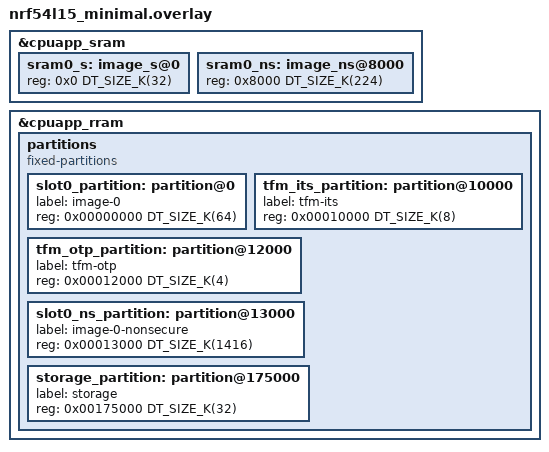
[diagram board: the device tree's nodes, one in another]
/*
 * Copyright (c) 2026 Nordic Semiconductor ASA
 *
 * SPDX-License-Identifier: LicenseRef-Nordic-5-Clause
 */

/*
 * Minimal TF-M partition layout for nRF54L15
 *
 * nRF54L15 has 1524 kB of RRAM and 256 kB of SRAM.
 * TrustZone flash region alignment: 4 kB (MPC-based)
 * TrustZone RAM region alignment:   4 kB
 * RRAM erase-block-size:            4 kB
 *
 * This layout uses the TF-M minimal profile with:
 * - No MCUboot (direct boot into TF-M)
 * - No Protected Storage partition (PS disabled in minimal profile)
 * - Minimal Internal Trusted Storage (ITS)
 * - Minimal OTP/NV counters area
 * - Maximized non-secure application space
 *
 * Suitable for: bootloader signature verification, minimal crypto,
 *               resource-constrained applications
 */

&cpuapp_sram {
	/* Minimal secure SRAM — just enough for TF-M minimal profile */
	sram0_s: image_s@0 {
		#address-cells = <1>;
		#size-cells = <1>;
		reg = <0x0 DT_SIZE_K(32)>;
		ranges = <0x0 0x0 DT_SIZE_K(32)>;
	};

	/* Non-Secure gets the remaining 224 kB */
	sram0_ns: image_ns@8000 {
		#address-cells = <1>;
		#size-cells = <1>;
		reg = <0x8000 DT_SIZE_K(224)>;
		ranges = <0x0 0x8000 DT_SIZE_K(224)>;
	};
};

&cpuapp_rram {
	partitions {
		compatible = "fixed-partitions";
		#address-cells = <1>;
		#size-cells = <1>;

		/*
		 * Flash layout (all addresses 4 kB aligned):
		 *
		 * 0x00000000  TF-M secure image        (64 kB)
		 * 0x00010000  TF-M ITS                  (8 kB)
		 * 0x00012000  TF-M OTP / NV counters    (4 kB)
		 * 0x00013000  Non-secure application  (1416 kB)
		 * 0x00175000  Non-secure storage        (32 kB)
		 */

		slot0_partition: partition@0 {
			label = "image-0";
			reg = <0x00000000 DT_SIZE_K(64)>;
		};

		tfm_its_partition: partition@10000 {
			label = "tfm-its";
			reg = <0x00010000 DT_SIZE_K(8)>;
		};

		tfm_otp_partition: partition@12000 {
			label = "tfm-otp";
			reg = <0x00012000 DT_SIZE_K(4)>;
		};

		slot0_ns_partition: partition@13000 {
			label = "image-0-nonsecure";
			reg = <0x00013000 DT_SIZE_K(1416)>;
		};

		storage_partition: partition@175000 {
			label = "storage";
			reg = <0x00175000 DT_SIZE_K(32)>;
		};
	};
};
